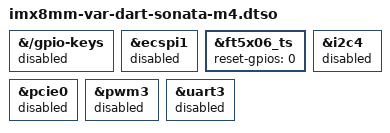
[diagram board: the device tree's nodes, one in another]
// SPDX-License-Identifier: (GPL-2.0+ OR MIT)
/*
 * Cortex-M4 support for Variscite DART-MX8M-MINI on Sonata-Board
 *
 * Link: https://variscite.com/carrier-boards/sonata-board/
 *
 * Copyright (C) 2026 Variscite Ltd. - https://www.variscite.com/
 *
 */

/dts-v1/;
/plugin/;

#include "imx8mm-var-common-m4.dtsi"

/* The buttons use a GPIO expander on I2C4. */
&{/gpio-keys} {
	status = "disabled";
};

/* Reserve the peripherals used by the Cortex-M4 firmware. */
&ecspi1 {
	status = "reserved";
};

/*
 * Keep the touchscreen enabled without its optional reset GPIO, since the
 * GPIO expander on I2C4 is unavailable to Linux.
 */
&ft5x06_ts {
	reset-gpios = <0>;
};

&i2c4 {
	status = "reserved";
};

/* The PCIe reset uses a GPIO expander on I2C4. */
&pcie0 {
	status = "disabled";
};

&pwm3 {
	status = "reserved";
};

&uart3 {
	status = "reserved";
};
